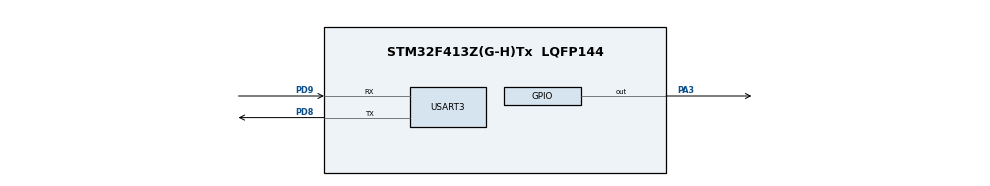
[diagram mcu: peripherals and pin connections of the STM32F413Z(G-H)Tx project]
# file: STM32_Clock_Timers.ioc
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Mcu.Family=STM32F4
Mcu.Name=STM32F413Z(G-H)Tx
Mcu.Package=LQFP144
NVIC.PriorityGroup=NVIC_PRIORITYGROUP_4
NVIC.TIM6_DAC_IRQn=true\:0\:0\:false\:false\:true\:true\:true\:true
NVIC.USART3_IRQn=true\:0\:0\:false\:false\:true\:true\:true\:true
PA13.Signal=SYS_JTMS-SWDIO
PA14.Signal=SYS_JTCK-SWCLK
PA3.Signal=GPIO_Output
PD8.Mode=Asynchronous
PD8.Signal=USART3_TX
PD9.Mode=Asynchronous
PD9.Signal=USART3_RX
ProjectManager.HeapSize=0x200
ProjectManager.StackSize=0x400
ProjectManager.TargetToolchain=STM32CubeIDE
RCC.CortexFreq_Value=16000000
RCC.USBFreq_Value=96000000
RCC.VCOOutputFreq_Value=192000000
TIM6.Period=65535-1
TIM6.Prescaler=16-1
USART3.VirtualMode=VM_ASYNC
VP_TIM6_VS_ClockSourceINT.Mode=Enable_Timer
board=custom

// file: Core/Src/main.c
/* USER CODE BEGIN Header */
/**
  ******************************************************************************
  * @file           : main.c
  * @brief          : Main program body
  ******************************************************************************
  * @attention
  *
  * Copyright (c) 2024 STMicroelectronics.
  * All rights reserved.
  *
  * This software is licensed under terms that can be found in the LICENSE file
  * in the root directory of this software component.
  * If no LICENSE file comes with this software, it is provided AS-IS.
  *
  ******************************************************************************
  */
/* USER CODE END Header */
#include "main.h"

/* USER CODE BEGIN Includes */
#include <stdio.h>
/* USER CODE END Includes */

/* USER CODE BEGIN PTD */
char buffer[50];
int buffer_len;
uint16_t timer_val;
/* USER CODE END PTD */

TIM_HandleTypeDef htim6;

UART_HandleTypeDef huart3;

void SystemClock_Config(void);
static void MX_GPIO_Init(void);
static void MX_TIM6_Init(void);
static void MX_USART3_UART_Init(void);

int main(void)
{

  /* MCU Configuration--------------------------------------------------------*/

  /* Reset of all peripherals, Initializes the Flash interface and the Systick. */
  HAL_Init();

  /* Configure the system clock */
  SystemClock_Config();

  /* Initialize all configured peripherals */
  MX_GPIO_Init();
  MX_TIM6_Init();
  MX_USART3_UART_Init();
  /* USER CODE BEGIN 2 */
  HAL_TIM_Base_Start_IT(&htim6);

  buffer_len = sprintf(buffer, "Measuring time test\r\n");
  HAL_UART_Transmit(&huart3, (uint8_t *) buffer, buffer_len, 100);
  /* USER CODE END 2 */

  /* Infinite loop */
  while (1)
  {

  }
}

void SystemClock_Config(void)
{
  RCC_OscInitTypeDef RCC_OscInitStruct = {0};
  RCC_ClkInitTypeDef RCC_ClkInitStruct = {0};

  /** Configure the main internal regulator output voltage
  */
  __HAL_RCC_PWR_CLK_ENABLE();
  __HAL_PWR_VOLTAGESCALING_CONFIG(PWR_REGULATOR_VOLTAGE_SCALE1);

  /** Initializes the RCC Oscillators according to the specified parameters
  * in the RCC_OscInitTypeDef structure.
  */
  RCC_OscInitStruct.OscillatorType = RCC_OSCILLATORTYPE_HSI;
  RCC_OscInitStruct.HSIState = RCC_HSI_ON;
  RCC_OscInitStruct.HSICalibrationValue = RCC_HSICALIBRATION_DEFAULT;
  RCC_OscInitStruct.PLL.PLLState = RCC_PLL_NONE;
  if (HAL_RCC_OscConfig(&RCC_OscInitStruct) != HAL_OK)
  {
    Error_Handler();
  }

  /** Initializes the CPU, AHB and APB buses clocks
  */
  RCC_ClkInitStruct.ClockType = RCC_CLOCKTYPE_HCLK|RCC_CLOCKTYPE_SYSCLK
                              |RCC_CLOCKTYPE_PCLK1|RCC_CLOCKTYPE_PCLK2;
  RCC_ClkInitStruct.SYSCLKSource = RCC_SYSCLKSOURCE_HSI;
  RCC_ClkInitStruct.AHBCLKDivider = RCC_SYSCLK_DIV1;
  RCC_ClkInitStruct.APB1CLKDivider = RCC_HCLK_DIV1;
  RCC_ClkInitStruct.APB2CLKDivider = RCC_HCLK_DIV1;

  if (HAL_RCC_ClockConfig(&RCC_ClkInitStruct, FLASH_LATENCY_0) != HAL_OK)
  {
    Error_Handler();
  }
}

static void MX_TIM6_Init(void)
{

  TIM_MasterConfigTypeDef sMasterConfig = {0};

  htim6.Instance = TIM6;
  htim6.Init.Prescaler = 16-1;
  htim6.Init.CounterMode = TIM_COUNTERMODE_UP;
  htim6.Init.Period = 65535-1;
  htim6.Init.AutoReloadPreload = TIM_AUTORELOAD_PRELOAD_DISABLE;
  if (HAL_TIM_Base_Init(&htim6) != HAL_OK)
  {
    Error_Handler();
  }
  sMasterConfig.MasterOutputTrigger = TIM_TRGO_RESET;
  sMasterConfig.MasterSlaveMode = TIM_MASTERSLAVEMODE_DISABLE;
  if (HAL_TIMEx_MasterConfigSynchronization(&htim6, &sMasterConfig) != HAL_OK)
  {
    Error_Handler();
  }

}

static void MX_USART3_UART_Init(void)
{

  huart3.Instance = USART3;
  huart3.Init.BaudRate = 115200;
  huart3.Init.WordLength = UART_WORDLENGTH_8B;
  huart3.Init.StopBits = UART_STOPBITS_1;
  huart3.Init.Parity = UART_PARITY_NONE;
  huart3.Init.Mode = UART_MODE_TX_RX;
  huart3.Init.HwFlowCtl = UART_HWCONTROL_NONE;
  huart3.Init.OverSampling = UART_OVERSAMPLING_16;
  if (HAL_UART_Init(&huart3) != HAL_OK)
  {
    Error_Handler();
  }

}

static void MX_GPIO_Init(void)
{
  GPIO_InitTypeDef GPIO_InitStruct = {0};

  /* GPIO Ports Clock Enable */
  __HAL_RCC_GPIOA_CLK_ENABLE();
  __HAL_RCC_GPIOD_CLK_ENABLE();

  /*Configure GPIO pin Output Level */
  HAL_GPIO_WritePin(GPIOA, GPIO_PIN_3, GPIO_PIN_RESET);

  /*Configure GPIO pin : PA3 */
  GPIO_InitStruct.Pin = GPIO_PIN_3;
  GPIO_InitStruct.Mode = GPIO_MODE_OUTPUT_PP;
  GPIO_InitStruct.Pull = GPIO_NOPULL;
  GPIO_InitStruct.Speed = GPIO_SPEED_FREQ_LOW;
  HAL_GPIO_Init(GPIOA, &GPIO_InitStruct);

}

/* USER CODE BEGIN 4 */
void HAL_TIM_PeriodElapsedCallback(TIM_HandleTypeDef * htim) {
	if (htim == &htim6) {
		//HAL_GPIO_TooglePin(GPIO_Debug_GPIO_Port, GPIO_Debug_Pin);
		timer_val = __HAL_TIM_GET_COUNTER(&htim6);
		for(int i=0; i<=100; i++);
		timer_val = __HAL_TIM_GET_COUNTER(&htim6) - timer_val;
		buffer_len  = sprintf(buffer, "%u ms\r\n", timer_val);
		HAL_UART_Transmit(&huart3, (uint8_t *) buffer, buffer_len, 10);
	}
}
/* USER CODE END 4 */

void Error_Handler(void)
{
  __disable_irq();
  while (1)
  {
  }
}
